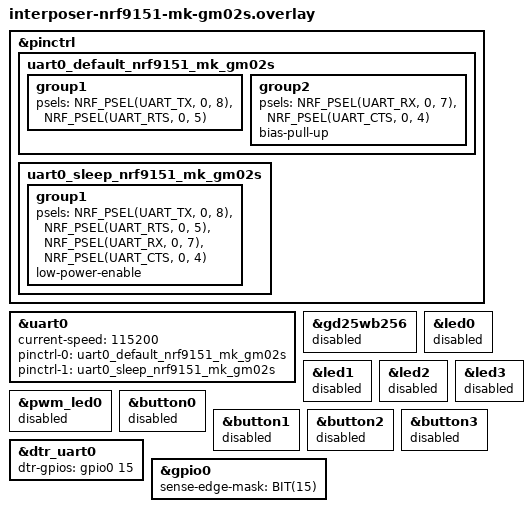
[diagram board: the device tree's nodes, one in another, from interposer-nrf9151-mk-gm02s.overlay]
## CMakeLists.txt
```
#
# Copyright (c) 2019 Nordic Semiconductor
#
# SPDX-License-Identifier: LicenseRef-Nordic-5-Clause
#

cmake_minimum_required(VERSION 3.20.0)

find_package(Zephyr REQUIRED HINTS $ENV{ZEPHYR_BASE})
project(serial_modem)

# NORDIC SDK APP START
target_sources(app PRIVATE src/main.c)
target_sources(app PRIVATE src/sm_util.c)
target_sources(app PRIVATE src/sm_ctrl_pin.c)
target_sources(app PRIVATE src/sm_settings.c)
target_sources(app PRIVATE src/sm_at_host.c)
target_sources(app PRIVATE src/sm_at_commands.c)
target_sources(app PRIVATE src/sm_at_socket.c)
target_sources(app PRIVATE src/sm_uart_handler.c)
target_sources(app PRIVATE src/sm_log.c)
target_sources(app PRIVATE src/sm_at_urc_filter.c)
# NORDIC SDK APP END
target_sources_ifdef(CONFIG_SM_FW_UPDATE app PRIVATE src/sm_fw_update.c)
target_sources_ifdef(CONFIG_SM_FOTA_SESSION app PRIVATE src/sm_fota_session.c)
target_sources_ifdef(CONFIG_SM_FOTA app PRIVATE src/sm_at_fota.c)
target_sources_ifdef(CONFIG_SM_DFU app PRIVATE src/sm_at_dfu.c)
target_sources_ifdef(CONFIG_SM_SMS app PRIVATE src/sm_at_sms.c)
target_sources_ifdef(CONFIG_SM_PPP app PRIVATE src/sm_ppp.c)
target_sources_ifdef(CONFIG_SM_CMUX app PRIVATE src/sm_cmux.c)
target_sources_ifdef(CONFIG_SM_ICMP app PRIVATE src/sm_at_icmp.c)
target_sources_ifdef(CONFIG_SM_GNSS app PRIVATE src/sm_at_gnss.c)
target_sources_ifdef(CONFIG_SM_NRF_CLOUD app PRIVATE src/sm_at_nrfcloud.c)
target_sources_ifdef(CONFIG_SM_NRF_CLOUD_OBSERVABILITY app PRIVATE src/sm_at_nrfcloud_obs.c)
target_sources_ifdef(CONFIG_SM_NRF_CLOUD_FOTA app PRIVATE src/sm_at_nrfcloud_fota.c)
target_sources_ifdef(CONFIG_SM_MQTTC app PRIVATE src/sm_at_mqtt.c)
target_sources_ifdef(CONFIG_SM_COAPC app PRIVATE src/sm_at_coap.c)
target_sources_ifdef(CONFIG_SM_HTTPC app PRIVATE src/sm_at_httpc.c)
target_sources_ifdef(CONFIG_SM_MODEM_TRACE_BACKEND_CMUX app PRIVATE src/sm_trace_backend_cmux.c)
target_sources_ifdef(CONFIG_SM_MODEM_TRACE_BACKEND_UART app PRIVATE src/sm_trace_backend_uart.c)
target_sources_ifdef(CONFIG_NRF_PROVISIONING app PRIVATE src/sm_at_provisioning.c)
target_sources_ifdef(CONFIG_SM_NRF_CLOUD_OBSERVABILITY_LTE_METRICS app PRIVATE src/sm_at_nrfcloud_obs_lte_metrics.c)

add_subdirectory_ifdef(CONFIG_SM_CARRIER src/lwm2m_carrier)

zephyr_include_directories(src)
zephyr_include_directories(memfault)

include(cmake/sm_version.cmake)
```

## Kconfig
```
#
# Copyright (c) 2019 Nordic Semiconductor
#
# SPDX-License-Identifier: LicenseRef-Nordic-5-Clause
#

menu "Nordic Serial Modem"

config HEAP_MEM_POOL_ADD_SIZE_SERIAL_MODEM
	int "Additional heap memory pool size for Serial Modem"
	default 1700 if SM_NRF_CLOUD
	default 0
	help
	  modem_jwt library used by nrf_cloud libraries, uses kernel heap for querying UUID.
	  2x CONFIG_MODEM_JWT_MAX_LEN is the maximum it can use.

config SM_BLOCKING_WORK_Q
	bool
	help
	  Work queue for operations that block for a long time.

config SM_BLOCKING_WORK_Q_STACK_SIZE
	int "Stack size for the blocking operations work queue"
	default 4096
	depends on SM_BLOCKING_WORK_Q

config SM_CUSTOMER_VERSION
	string "Customer version string"
	help
	   This version is reported together with baseline versions by AT command "#XSMVER".

#
# external XTAL for UART
#
config SM_EXTERNAL_XTAL
	bool "Use external XTAL for UARTE"

#
# AT command terminator
#
choice
	prompt "Termination mode"
	default SM_CR_TERMINATION
	help
	  Sets the command terminator used by the serial terminal.
	  Available options are:
	  -  CR termination
	  -  LF termination
	  -  CR+LF termination

config SM_CR_TERMINATION
	bool "CR termination"

config SM_LF_TERMINATION
	bool "LF termination"

config SM_CR_LF_TERMINATION
	bool "CR+LF termination"

endchoice

#
# UART buffers (when CMUX is not in use)
#
config SM_UART_RX_BUF_COUNT
	int "Receive buffers for UART"
	range 2 4
	default 3
	help
	  Amount of buffers for receiving (RX) UART traffic.
	  If the buffers are full, UART RX will be disabled until the buffers are processed.
	  These buffers are not used when CMUX is in use.

config SM_UART_RX_BUF_SIZE
	int "Receive buffer size for UART"
	range 128 4096
	default 2048 if $(dt_nodelabel_enabled,uart0) = y && \
			$(dt_nodelabel_bool_prop,uart0,hw-flow-control) = n
	default 2048 if $(dt_nodelabel_enabled,uart2) = y && \
			$(dt_nodelabel_bool_prop,uart2,hw-flow-control) = n
	default 532 if SM_CMUX
	default 256
	help
	  Amount of received (RX), unprocessed, UART traffic that can be held by single buffer.
	  Increase buffer space if UART0 or UART2 lacks hardware flow control.

config SM_UART_TX_BUF_SIZE
	int "Send buffer size for UART"
	range 128 4096
	default 532 if SM_CMUX
	default 256
	help
	  Amount of UART traffic waiting to be sent (TX), that can be held.
	  If the buffers are full, will send synchronously.

config SM_URC_BUFFER_SIZE
	int "TX buffer size for unsolicited result codes (URC)"
	range 128 4096
	default 4096
	help
	  Buffer, in which unsolicited result codes (URC) are stored before being sent to the host.
	  The buffer has to be large enough to hold the largest URC that can be sent by the modem.
	  Result codes longer than this size will get dropped.

	  The URC in here means an URC from the Modem or from a thread which is not serving sm_work_queue.
	  Messages that are originally sent from sm_work_queue are part of AT-command responses, even though they are indistinguishable from the URCs.

	  This can be reduced if your use cases do not require lengthy notifications.
	  Note: %NCELLMEAS notifications can be nearly 4kB in size,
	  which explains the default value.
	  The maximum value is the size of the buffer that the result codes are formatted in.

config SM_AT_ECHO_MAX_LEN
	int "Maximum length of AT command echo"
	range 2 4096
	default 4096
	help
	  Maximum length of AT command echo that will be sent back to the host when AT command echo is enabled.
	  AT commands longer than this value will be truncated in the echo.
	  The AT command terminator is included in this length and it is always echoed.

config SM_URC_DELAY_WITH_INCOMPLETE_ECHO_MS
	int "Delay for URC transmission when incomplete AT command echo is in progress (ms)"
	default 1000
	help
	  When AT command echo is enabled, and the command is spread over multiple RX buffers,
	  due to its length, or the speed of incoming data (typing), the command echo is considered incomplete
	  until the final part of the command (terminating character) has been received and echoed back to the host.

	  When the AT command echo is incomplete, URC transmissions are delayed by this amount of time for every
	  RX buffer (keystroke, while typing) received until the command echo is complete.

#
# Automatic network attach
#
config SM_AUTO_CONNECT
	bool "Automatically connect to the network on start-up or after a reset"
	help
	  Enables automatic connection to the network using the PDN configuration.

if SM_AUTO_CONNECT

config SM_AUTO_CONNECT_SYSTEM_MODE
	string "System mode for automatic network attach"
	default "1,1,1,0"
	help
	  Defines the default system mode using '%XSYSTEMMODE' AT command for automatic network attach.
	  The format is a comma-separated list of four integers. See the AT command reference for +XSYSTEMMODE for more details.
	  Default value enables LTE-M, NB-IoT, and GNSS, with no LTE preference.

config SM_AUTO_CONNECT_PDN_CONFIG
	bool "PDN configuration for automatic network attach"
	help
	  Enables sending of PDN configuration during automatic network attach.

if SM_AUTO_CONNECT_PDN_CONFIG

config SM_AUTO_CONNECT_PDN_APN
	string "APN for automatic network attach"
	default ""
	help
	  APN to use for automatic network attach.
	  If left empty, the APN configured in the modem will be used.

choice SM_AUTO_CONNECT_PDN_FAMILY
	prompt "PDN family (IP type) for automatic network attach"
	default SM_AUTO_CONNECT_PDN_FAMILY_IPV4V6
	help
	  Select the PDN family (IP address type) to use for automatic network attach.
	  See AT command reference for +CGDCONT for more details.

config SM_AUTO_CONNECT_PDN_FAMILY_IP
	bool "IPv4"
	help
	  Use IPv4 only for the PDN connection.

config SM_AUTO_CONNECT_PDN_FAMILY_IPV6
	bool "IPv6"
	help
	  Use IPv6 only for the PDN connection.

config SM_AUTO_CONNECT_PDN_FAMILY_IPV4V6
	bool "IPv4 and IPv6"
	help
	  Use both IPv4 and IPv6 for the PDN connection (dual stack).

config SM_AUTO_CONNECT_PDN_FAMILY_NON_IP
	bool "Non-IP"
	help
	  Use Non-IP PDN type for the connection.
	  This is used for data transmission without IP headers.

endchoice

config SM_AUTO_CONNECT_PDN_FAMILY_STRING
	string
	default "IP" if SM_AUTO_CONNECT_PDN_FAMILY_IP
	default "IPV6" if SM_AUTO_CONNECT_PDN_FAMILY_IPV6
	default "IPV4V6" if SM_AUTO_CONNECT_PDN_FAMILY_IPV4V6
	default "Non-IP" if SM_AUTO_CONNECT_PDN_FAMILY_NON_IP
	help
	  Internal use only. Represents the selected PDN family as a string.

config SM_AUTO_CONNECT_PDN_AUTH
	int "PDN authentication type for automatic network attach"
	default 0
	range 0 2
	help
	  PDN authentication type to use for automatic network attach.
	  0 = None
	  1 = PAP
	  2 = CHAP

config SM_AUTO_CONNECT_PDN_USERNAME
	string "PDN username for automatic network attach"
	default ""
	help
	  PDN username to use for automatic network attach.
	  Leave empty if no username is required.

config SM_AUTO_CONNECT_PDN_PASSWORD
	string "PDN password for automatic network attach"
	default ""
	help
	  PDN password to use for automatic network attach.
	  Leave empty if no password is required.

endif # SM_AUTO_CONNECT_PDN_CONFIG
endif # SM_AUTO_CONNECT

#
# Data mode
#
config SM_DATAMODE_TERMINATOR
	string "Pattern string to terminate data mode"
	default "+++"
	help
	  Use a pattern to terminate data mode

config SM_DATAMODE_BUF_SIZE
	int "Buffer size for data mode"
	range 1024 8192
	default 4096
	help
	  Size of the buffer for data received in data mode.

#
# Configurable services
#
config SM_SMS
	bool "SMS support"
	default y
	select SMS
	help
	  Support SMS send/receive in plain text

config SM_GNSS
	bool "GNSS support"
	default y

config SM_ICMP
	bool "ICMP ping support"
	default y
	select SM_BLOCKING_WORK_Q
	help
	  Enable the ping command for sending ICMP echo requests.

config SM_COAPC
	bool "CoAP client support"
	default y
	select COAP
	select COAP_CLIENT
	help
	  Enable CoAP client AT commands for making CoAP requests.

config SM_MQTTC
	bool "MQTT client support"
	default y
	select MQTT_LIB
	select MQTT_LIB_TLS

configdefault MQTT_CLEAN_SESSION
	default y if SM_MQTTC

config SM_FULL_FOTA
	bool "Full modem FOTA support"

config SM_DFU_MODEM_FULL
	bool "Full modem DFU support"

config SM_PPP
	bool "PPP support"

config SM_CMUX
	bool "CMUX support"

config SM_CMUX_CHANNEL_COUNT
	int "Number of CMUX channels" if SM_CMUX
	default 4 if SM_CMUX
	default 1 if !SM_CMUX
	range 1 63
	help
	  Number of channels to be used by the CMUX implementation.
	  Each channel adds about 4 kB of RAM usage for buffers.

config SM_DEBUG_STATS_HEAP
	bool "Enable heap usage statistics"
	default y
	select SYS_HEAP_RUNTIME_STATS
	help
	  Enable heap usage statistics for debugging purposes through AT#XDBGSTATSMEM command.
	  The statistics are printed to the log so use AT#XLOG=1 to enable logging.

config SM_DEBUG_STATS_THREAD_STACK
	bool "Enable threads' stack usage statistics"
	depends on SM_DEBUG_STATS_HEAP
	select THREAD_ANALYZER
	select THREAD_NAME
	help
	  Enable threads' stack usage statistics for debugging purposes through
	  the AT#XDBGSTATSMEM command. The statistics are printed to the log so use
	  AT#XLOG=1 to enable logging.
	  With default logging configurations, some of the stack usage metrics are dropped.
	  You need to increase CONFIG_LOG_BUFFER_SIZE to 2048 or more to make it work.
	  This feature will use 4-5 kB of FLASH.

if SM_PPP

config SM_PPP_FALLBACK_MTU
	int "Fallback MTU to be used by PPP"
	default 1280
	help
	  PPP tries to retrieve the cellular link MTU from the modem (using `AT+CGCONTRDP`).
	  If no MTU is returned by the modem, this value will be used as a fallback.
	  The MTU will be used for sending and receiving of data on both the PPP and cellular links.

endif # SM_PPP

if SM_CMUX || SM_PPP

config SM_MODEM_PIPE_TIMEOUT
	int "Timeout for the CMUX and PPP modem pipe operations in seconds"
	default 10

endif # SM_CMUX || SM_PPP

if SM_MQTTC

config SM_MQTTC_MESSAGE_BUFFER_LEN
	int "Size of the buffer for MQTT library"
	default 512
	help
	  Specifies maximum message size that can be transmitted/received through
	  MQTT (excluding MQTT PUBLISH payload).

config SM_MQTTC_VERSION_5_0
	bool "MQTT 5.0 support [EXPERIMENTAL]"
	default y
	help
	  Build the MQTT library with MQTT 5.0 protocol support.
	  The MQTT client uses MQTT 3.1.1 unless MQTT 5.0 is selected with
	  the AT#XMQTTCFG command.

choice MQTT_VERSION_SUPPORT
	default MQTT_VERSION_5_0 if SM_MQTTC_VERSION_5_0
endchoice

config SM_MQTTC_TOPIC_ALIAS_MAX
	int "Maximum number of outgoing MQTT 5.0 topic aliases"
	depends on SM_MQTTC_VERSION_5_0
	range 0 16
	default 4
	help
	  Number of topic aliases the MQTT client assigns to the topics of its own
	  MQTT 5.0 publications, limited by the broker's Topic Alias Maximum.
	  Repeated publications to an aliased topic omit the topic name.
	  Each alias uses about 130 bytes of heap while connected.
	  Set to 0 to disable outgoing topic aliases.
	  MQTT_TOPIC_ALIAS_MAX is a separate MQTT library option that limits the
	  topic aliases the broker uses in messages to the client.

# Incoming topic names can be longer than any fixed alias buffer, because wildcard
# subscriptions match topics of any length. The library drops the connection when an
# aliased topic does not fit, so do not advertise topic alias support by default.
# To enable, also set MQTT_TOPIC_ALIAS_STRING_MAX to at least SM_MQTTC_MESSAGE_BUFFER_LEN.
configdefault MQTT_TOPIC_ALIAS_MAX
	default 0

endif # SM_MQTTC

if SM_GNSS

config SM_GNSS_OUTPUT_NMEA_SATELLITES
	bool "Output NMEA satellite messages (GSV, GSA)"
	default y if SM_LOG_LEVEL_DBG
	depends on SM_LOG_LEVEL_DBG
	help
	  If enabled, NMEA messages that pertain to the satellites will be output
	  along with the other NMEA messages. Those are output in debug logs.

config SM_PGPS_INJECT_FIX_DATA
	bool "Inject the data obtained when acquiring a fix"
	default y
	depends on SM_GNSS
	depends on SM_NRF_CLOUD
	depends on NRF_CLOUD_PGPS
	help
	  If enabled, when a fix is acquired the current location and time will
	  be passed to the P-GPS subsystem.
	  It allows to speed up the time it takes to acquire the next fix when
	  A-GNSS is disabled or unavailable.
	  This can be detrimental to short TTFF if the device is expected to move
	  distances longer than a few dozen kilometers between fix attempts.
	  In that case this option should be disabled.

endif # SM_GNSS

config SM_HTTPC
	bool "HTTP client support"
	default y
	help
	  Enable HTTP client AT commands for making HTTP/HTTPS requests.
	  Uses non-blocking socket API with XAPOLL for asynchronous
	  event-driven I/O.

if SM_HTTPC

config SM_HTTPC_RESPONSE_TIMEOUT_MS
	int "HTTP client idle timeout (ms)"
	range 1000 300000
	default 30000
	help
	  The timer is a sliding window: it resets each time data is sent or
	  received (request headers, body upload chunks, response body chunks).
	  If no activity occurs within this window the request is aborted and
	  ``#XHTTPCSTAT: <fd>,-1,<bytes>`` is reported.
	  A periodic background scan enforces the deadline even when the
	  server stalls silently without closing the TCP connection.

endif # SM_HTTPC

if NRF_MODEM_LIB_TRACE

choice NRF_MODEM_LIB_TRACE_BACKEND

config SM_MODEM_TRACE_BACKEND_CMUX
	bool "CMUX modem trace backend"
	depends on SM_CMUX_CHANNEL_COUNT > 2
	help
	  When CMUX is enabled, modem traces are transmitted on a dedicated CMUX channel.
	  The trace channel is the first channel after the AT command channel and the PPP channel.

config SM_MODEM_TRACE_BACKEND_UART
	bool "UART modem trace backend (shared with Zephyr log backend)"
	depends on UART_ASYNC_API
	help
	  Uses the zephyr,console UART as the modem trace backend, sharing it
	  with the Zephyr application log backend. The two are mutually exclusive:
	  only one can be active at a time. Switch at runtime with AT#XLOG / AT#XTRACE.

endchoice # NRF_MODEM_LIB_TRACE_BACKEND

endif

#
# Hardware RX byte counting for UART
#
# Either hardware flow control OR hardware RX byte counting is required to prevent RX data loss.
# When hw-flow-control is enabled in devicetree, it handles flow management efficiently.
# When hw-flow-control is disabled, hardware RX byte counting is enabled to prevent data loss,
# but it consumes more power due to additional timer usage.
#
if UART_ASYNC_API

config UART_0_NRF_HW_ASYNC
	default y if HAS_HW_NRF_UARTE0 && !$(dt_nodelabel_bool_prop,uart0,hw-flow-control)

config UART_0_NRF_HW_ASYNC_TIMER
	default 0 if HAS_HW_NRF_UARTE0 && !$(dt_nodelabel_bool_prop,uart0,hw-flow-control)

config UART_2_NRF_HW_ASYNC
	default y if HAS_HW_NRF_UARTE2 && !$(dt_nodelabel_bool_prop,uart2,hw-flow-control)

config UART_2_NRF_HW_ASYNC_TIMER
	default 2 if HAS_HW_NRF_UARTE2 && !$(dt_nodelabel_bool_prop,uart2,hw-flow-control)

endif # UART_ASYNC_API

module = SM
module-str = serial modem
source "$(ZEPHYR_BASE)/subsys/logging/Kconfig.template.log_config"

rsource "src/lwm2m_carrier/Kconfig"

endmenu

# Must be sourced before Kconfig.zephyr, see the respective files for the reason why.
rsource "Kconfig.nrf_cloud"
rsource "Kconfig.memfault"

source "Kconfig.zephyr"
```

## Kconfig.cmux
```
#
# Copyright (c) 2026 Nordic Semiconductor ASA
#
# SPDX-License-Identifier: LicenseRef-Nordic-5-Clause
#

# Application defaults for CMUX, which is enabled by setting CONFIG_SM_CMUX=y.
#
# This file must be sourced before Kconfig.zephyr, which is what pulls in the Kconfig of
# the Zephyr modem subsystem: a default is inserted at the position where it appears
# relative to the definition of the symbol, and the first matching default wins. Sourced
# afterwards, every default here would silently lose to the one of the module.

if SM_CMUX

# Enable the Zephyr modem CMUX multiplexer.
configdefault MODEM_CMUX
	default y

# Set CMUX MTU to 127 bytes to align with the Linux gsm_mux driver default.
configdefault MODEM_CMUX_MTU
	default 127

# Extra work-buffer space for CMUX frame assembly.
# 127 (MTU) + 272 (header + flag overhead per frame) = 399 bytes.
configdefault MODEM_CMUX_WORK_BUFFER_SIZE_EXTRA
	default 399

endif # SM_CMUX
```

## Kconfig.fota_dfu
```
#
# Copyright (c) 2026 Nordic Semiconductor ASA
#
# SPDX-License-Identifier: LicenseRef-Nordic-5-Clause
#

# Firmware update features, together with the Kconfig defaults they pull in.
#
# SM_FOTA enables the AT#XFOTA command (firmware download over HTTP/HTTPS).
# SM_DFU  enables the AT#XDFU* commands (local firmware upload).
#
# Features that update the firmware, including SM_NRF_CLOUD_FOTA and the LwM2M carrier library,
# share the code that is behind the hidden symbols below:
# - SM_FOTA_SESSION: the state of a FOTA session and the reporting of its result.
# - SM_FW_UPDATE: the functionality common to all firmware updates, like the confirmation
#   of a new application image.
#
# This file must be sourced before Kconfig.zephyr, see Kconfig.nrf_cloud for the reason why.

config SM_FOTA
	bool "FOTA (Firmware Over-The-Air) support"
	default y
	select HTTP_PARSER_URL
	help
	  Enable FOTA support via the AT#XFOTA command.

config SM_FULL_FOTA
	bool "Full modem FOTA support"
	depends on SM_FOTA

config SM_DFU
	bool "DFU (Device Firmware Update) support"
	default y
	help
	  Enable DFU support via the AT#XDFUINIT, AT#XDFUWRITE and AT#XDFUAPPLY commands.

config SM_DFU_MODEM_FULL
	bool "Full modem DFU support"
	depends on SM_DFU

config SM_FOTA_SESSION
	bool
	default y if SM_FOTA || SM_NRF_CLOUD_FOTA

config SM_FW_UPDATE
	bool
	default y if SM_FOTA_SESSION || SM_DFU

# The LwM2M carrier library depends on DOWNLOADER and DFU_TARGET, so the hidden symbols cannot
# depend on it, as that would make a dependency loop. SM_CARRIER depends on SM_FOTA_SESSION instead.

if SM_FOTA_SESSION

# FOTA download library: handles OTA download and DFU target selection.
configdefault FOTA_DOWNLOAD
	default y

configdefault FOTA_DOWNLOAD_PROGRESS_EVT
	default y

# Downloader library used by fota_download.
configdefault DOWNLOADER
	default y

configdefault DOWNLOADER_STACK_SIZE
	default 4096

configdefault DOWNLOADER_MAX_FILENAME_SIZE
	default 2048

# Progressive slot erase during FOTA download.
configdefault IMG_ERASE_PROGRESSIVELY
	default y

endif # SM_FOTA_SESSION

if SM_FW_UPDATE

# DFU target library: used by FOTA (streaming download targets) and DFU
# (direct write targets: MCUboot, modem delta, full modem).
configdefault DFU_TARGET
	default y

# Stream flash: required internally by the DFU target library for all targets
# that write to flash in chunks.
configdefault STREAM_FLASH
	default y

# MCUboot image manager: required for confirming and scheduling MCUboot updates.
configdefault IMG_MANAGER
	default y

# MCUboot bootloader FOTA requires fw_info to validate the update after reboot.
configdefault FW_INFO
	default y

endif # SM_FW_UPDATE
```

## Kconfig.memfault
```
#
# Copyright (c) 2026 Nordic Semiconductor ASA
#
# SPDX-License-Identifier: LicenseRef-Nordic-5-Clause
#

# Application defaults for nRF Cloud observability and FOTA, i.e., Memfault features.
#
# This file must be sourced before Kconfig.zephyr, which is what pulls in the Kconfig of
# the Memfault module: a default is inserted at the position where it appears relative to
# the definition of the symbol, and the first matching default wins. Sourced afterwards,
# every default here would silently lose to the one of the module.

# Enable Memfault when the observability or FOTA features are on.
# Disable explicitly with CONFIG_MEMFAULT=n (no_memfault build), or automatically when both
# SM_NRF_CLOUD_OBSERVABILITY and SM_NRF_CLOUD_FOTA are disabled.
# Note: SM_NRF_CLOUD_OBSERVABILITY and SM_NRF_CLOUD_FOTA intentionally do not depend on
# MEMFAULT or MEMFAULT_USE_NRF_CLOUD_COAP. Those dependencies would be circular here.
# MEMFAULT_USE_NRF_CLOUD_COAP is enabled via its own configdefault below once MEMFAULT=y.
configdefault MEMFAULT
	default y if SM_NRF_CLOUD_OBSERVABILITY || SM_NRF_CLOUD_FOTA

config SM_NRF_CLOUD_OBSERVABILITY
	bool "nRF Cloud observability AT commands"
	default y
	depends on SM_NRF_CLOUD
	select BASE64
	help
	  Enables the ``AT#XNRFCLOUDOBS*`` commands, which control the Memfault data upload
	  over the nRF Cloud CoAP transport.
	  This requires :option:`CONFIG_SM_NRF_CLOUD`.
	  See :ref:`SM_AT_NRFCLOUDOBS` for more information.

config SM_NRF_CLOUD_OBSERVABILITY_AUTO_INTERVAL_SECONDS
	int "Default interval of the automatic upload"
	depends on SM_NRF_CLOUD_OBSERVABILITY
	default 3600
	range 60 86400
	help
	  Interval, in seconds, used by ``AT#XNRFCLOUDOBSAUTO`` when the host enables the
	  automatic upload without giving one, and no interval has been stored
	  yet. The interval the host gives is persistent, so this value only
	  applies until the host configures one.
	  It defaults to one hour.
	  This requires :option:`CONFIG_SM_NRF_CLOUD_OBSERVABILITY` to be enabled.

config SM_NRF_CLOUD_OBSERVABILITY_DEBUG
	bool "Debug nRF Cloud observability AT commands"
	depends on SM_NRF_CLOUD_OBSERVABILITY
	help
	  Enable the debug observability commands:

	  * ``AT#XNRFCLOUDOBSDEVINFO`` returns the Memfault device information.
	  * ``AT#XNRFCLOUDOBSCRASH`` forces a crash so that coredump capture and
	    upload can be tested.
	  * ``AT#XNRFCLOUDOBSEXPORT`` prints the buffered Memfault chunks to the AT
	    interface instead of uploading them.

	  This is disabled by default: ``AT#XNRFCLOUDOBSCRASH`` deliberately crashes
	  the application, so enable it only in development builds.
	  This requires :option:`CONFIG_SM_NRF_CLOUD_OBSERVABILITY` to be enabled.

config SM_NRF_CLOUD_OBSERVABILITY_LTE_METRICS
	bool "Collect additional LTE metrics via AT commands for Memfault"
	depends on MEMFAULT
	depends on MEMFAULT_NCS_LTE_METRICS
	depends on SM_NRF_CLOUD_OBSERVABILITY
	default y
	help
	  Collect cell ID, tracking area code, LTE mode, PSM (TAU and active time) and
	  eDRX (interval and paging time window) metrics on each Memfault heartbeat.
	  Also track time to connect, connection-loss count, and LTE on-time.
	  It is enabled by default.
	  This requires :option:`CONFIG_SM_NRF_CLOUD_OBSERVABILITY`.

config SM_NRF_CLOUD_FOTA
	bool "nRF Cloud FOTA AT commands"
	default y
	depends on SM_NRF_CLOUD
	help
	  Enables the ``AT#XNRFCLOUDFOTA*`` commands, which check for and download
	  application and modem firmware updates using `Memfault release management`_,
	  delivered over the same nRF Cloud CoAP transport as ``AT#XNRFCLOUDOBS*``.
	  This requires :option:`CONFIG_SM_NRF_CLOUD`.
	  See :ref:`SM_AT_NRFCLOUDFOTA` for more information.

# Report a statically configured firmware version. A choice symbol cannot be given a
# configdefault, which warns that it has no effect, so the default of the choice itself is
# overridden instead. Assigning the symbol in prj.conf would warn with CONFIG_MEMFAULT=n.
choice MEMFAULT_FW_VERSION
	default MEMFAULT_NCS_FW_VERSION_STATIC
endchoice

configdefault MEMFAULT_LOGGING_ENABLE
	default y

# The whole buffer is a static RAM array captured via .bss regardless of how much of it is in use.
configdefault MEMFAULT_LOGGING_RAM_SIZE
	default 4096 if $(dt_nodelabel_exists,memfault_coredump_partition)

# Return from the fault handler to allow Zephyr's default fatal error handler to take over.
configdefault MEMFAULT_FAULT_HANDLER_RETURN
	default y

configdefault MEMFAULT_RAM_BACKED_COREDUMP_SIZE
	default 4096

# The flash-backed coredump is enabled automatically when the board's devicetree defines a
# memfault_coredump_partition falling back to a RAM-backed coredump otherwise.
configdefault MEMFAULT_NCS_INTERNAL_FLASH_BACKED_COREDUMP
	default y if $(dt_nodelabel_exists,memfault_coredump_partition)

# Crashing thread benefits from a deep stack capture.
configdefault MEMFAULT_COREDUMP_ACTIVE_TASK_STACK_SIZE_TO_COLLECT
	default 2048 if $(dt_nodelabel_exists,memfault_coredump_partition)

# The ~13 other blocked / idle threads need to show a couple of frames to tell
# what the thread was waiting on.
configdefault MEMFAULT_COREDUMP_STACK_SIZE_TO_COLLECT
	default 256

configdefault MEMFAULT_COREDUMP_MAX_TRACKED_TASKS
	default 16

# Disable .data collection.
configdefault MEMFAULT_COREDUMP_COLLECT_DATA_REGIONS
	default n

# Collect heap statistics in coredumps.
configdefault MEMFAULT_HEAP_STATS
	default y

# Upload Memfault data via the nRF Cloud CoAP transport.
configdefault MEMFAULT_USE_NRF_CLOUD_COAP
	default y

configdefault MEMFAULT_HTTP_ENABLE
	default n

# The periodic upload port is not used: AT#XNRFCLOUDOBSAUTO implements the automatic upload
# itself, with an interval that the host can change, and every other upload is host-driven
# with AT#XNRFCLOUDOBSUPLOAD.
configdefault MEMFAULT_PERIODIC_UPLOAD
	default n

# Enabled by SM_NRF_CLOUD_FOTA (AT#XNRFCLOUDFOTA*); no backend is wired up otherwise.
configdefault MEMFAULT_ZEPHYR_FOTA
	default y if SM_NRF_CLOUD_FOTA
	default n

configdefault MEMFAULT_FOTA_DOWNLOAD_CALLBACK_CUSTOM
	default y if SM_NRF_CLOUD_FOTA

configdefault MEMFAULT_FOTA_MODEM_UPDATE
	default y if SM_NRF_CLOUD_FOTA

configdefault NRF_CLOUD_FOTA_POLL
	default y if SM_NRF_CLOUD_FOTA

# Collect metrics for unused stack space.
configdefault MEMFAULT_NCS_STACK_METRICS
	default n

# Collect the LTE metrics that MODEM_INFO provides: modem firmware version, operator, RSRP,
# SNR, band and the connectivity statistics. The remaining LTE metrics are collected via
# AT commands in sm_at_nrfcloud_obs_lte_metrics.c.
configdefault MEMFAULT_NCS_LTE_METRICS
	default y

configdefault MEMFAULT_USER_CONFIG_ENABLE
	default y if SM_NRF_CLOUD_OBSERVABILITY_LTE_METRICS

configdefault MEMFAULT_NCS_IMPLEMENT_METRICS_COLLECTION
	default n if SM_NRF_CLOUD_OBSERVABILITY_LTE_METRICS

# Memfault depends on POSIX, disable unneeded POSIX features.
configdefault POSIX_FILE_SYSTEM
	default n if MEMFAULT

# The Memfault CoAP port (memfault_platform_coap.c) allocates the packetizer buffer with
# k_calloc, and it fails to build unless CONFIG_HEAP_MEM_POOL_SIZE is greater than zero. A
# HEAP_MEM_POOL_ADD_SIZE_* option is not enough, because the port tests this symbol
# directly. Zephyr uses the greater of this value and the sum of the
# HEAP_MEM_POOL_ADD_SIZE_* options, so this does not shrink the pool of other subsystems.
configdefault HEAP_MEM_POOL_SIZE
	default 4096 if MEMFAULT

# MEMFAULT_USE_NRF_CLOUD_COAP requires at least two user CoAP options (the project key for
# the chunks resource, and PROXY_URI plus the project key for the proxy resource), an
# extended options length value of at least 192, and room for four extra CoAP client
# options.
configdefault NRF_CLOUD_COAP_MAX_USER_OPTIONS
	default 2 if MEMFAULT

configdefault COAP_EXTENDED_OPTIONS_LEN_VALUE
	default 192 if MEMFAULT
	default 96

configdefault COAP_CLIENT_MAX_EXTRA_OPTIONS
	default 4 if MEMFAULT

configdefault COAP_CLIENT_MAX_PATH_LENGTH
	default 160 if MEMFAULT_USE_NRF_CLOUD_COAP

# The larger CoAP options above (COAP_EXTENDED_OPTIONS_LEN_VALUE and
# COAP_CLIENT_MAX_EXTRA_OPTIONS) enlarge struct coap_client_request, which the
# nRF Provisioning thread builds on its stack in send_coap_request(),
# so the stack size must be increased to accommodate it.
configdefault NRF_PROVISIONING_STACK_SIZE
	default 2560 if MEMFAULT
```

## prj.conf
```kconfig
#
# Copyright (c) 2020 Nordic Semiconductor ASA
#
# SPDX-License-Identifier: LicenseRef-Nordic-5-Clause
#
# General config
CONFIG_LOG=y
CONFIG_ASSERT=y
CONFIG_ASSERT_VERBOSE=n
CONFIG_LOG_DEFAULT_LEVEL=3
CONFIG_STACK_SENTINEL=y
CONFIG_PICOLIBC_IO_FLOAT=y
CONFIG_RING_BUFFER=y
CONFIG_REBOOT=y
CONFIG_EVENTFD=y
CONFIG_NCS_APPLICATION_BOOT_BANNER_STRING="Serial Modem"

# Enable UART logging by default.
CONFIG_UART_CONSOLE=y
CONFIG_LOG_BACKEND_UART=y
# Logging starts automatically, but it is disabled after bootup.
CONFIG_LOG_BACKEND_UART_AUTOSTART=y

# Disable Segger RTT logging by default.
CONFIG_USE_SEGGER_RTT=n
CONFIG_RTT_CONSOLE=n
CONFIG_LOG_BACKEND_RTT=n
# Optional: when RTT logging is enabled, increase the RTT buffer so that
# all Serial Modem boot logs fit into the buffer.
#CONFIG_SEGGER_RTT_BUFFER_SIZE_UP=2048

# Enable Serial Modem debug logging by default. This is required for AT#XLOG=2.
CONFIG_SM_LOG_LEVEL_DBG=y

# Network
CONFIG_NETWORKING=y
CONFIG_NET_SOCKETS=y
CONFIG_NET_NATIVE=n
CONFIG_NET_IPV4=y
CONFIG_NET_IPV6=y

# Modem library
CONFIG_NRF_MODEM_LIB=y
CONFIG_AT_CMD_CUSTOM=y

# Modem pipe
CONFIG_MODEM_MODULES=y
CONFIG_MODEM_PIPE=y
CONFIG_MODEM_CMUX=y

# Handle modem fault
CONFIG_NRF_MODEM_LIB_ON_FAULT_APPLICATION_SPECIFIC=y

# Use GPIO
CONFIG_GPIO=y
CONFIG_GPIO_NRFX=y

# UART interface
CONFIG_SERIAL=y
CONFIG_UART_USE_RUNTIME_CONFIGURE=y
CONFIG_UART_ASYNC_API=y
CONFIG_UART_INTERRUPT_DRIVEN=n

# Stacks and heaps
CONFIG_MAIN_STACK_SIZE=2048
CONFIG_SYSTEM_WORKQUEUE_STACK_SIZE=4096
CONFIG_AT_MONITOR_HEAP_SIZE=4096
CONFIG_COMMON_LIBC_MALLOC=y
CONFIG_COMMON_LIBC_MALLOC_ARENA_SIZE=-1

# Device power management
CONFIG_PM_DEVICE=y
CONFIG_PM_DEVICE_RUNTIME=n

# FLASH
CONFIG_FLASH=y
CONFIG_FLASH_PAGE_LAYOUT=y
CONFIG_FLASH_MAP=y
CONFIG_MPU_ALLOW_FLASH_WRITE=y

# Settings
CONFIG_SETTINGS=y
CONFIG_SETTINGS_NVS=y
CONFIG_NVS=y

# Reset on fatal error instead of halting.
CONFIG_RESET_ON_FATAL_ERROR=y

# CoAP client settings
CONFIG_COAP_CLIENT_BLOCK_SIZE=512
CONFIG_COAP_CLIENT_MESSAGE_SIZE=576
CONFIG_COAP_CLIENT_THREAD_PRIORITY=0
# COAP_EXTENDED_OPTIONS_LEN_VALUE and COAP_CLIENT_MAX_EXTRA_OPTIONS are set in
# Kconfig.memfault, which bumps them when Memfault is enabled.
CONFIG_COAP_CLIENT_STACK_SIZE=2048

# UUID and JWT
CONFIG_MODEM_JWT=y

# Disabling antenna configurations since GNSS uses external antenna by default.
# Modem antenna library is enabled by default for nRF9151DK with onboard antenna configuration.
# If you need to use the onboard antenna, use "AT%XCOEX0=1,1,1565,1586" command.
CONFIG_MODEM_ANTENNA=n

# AT command helper libraries
CONFIG_AT_PARSER=y
CONFIG_AT_MONITOR=y

# SMS
CONFIG_SMS_STATUS_REPORT=n

# Eventfd's to use with AT-commands.
CONFIG_ZVFS_EVENTFD_MAX=2

# TF-M
CONFIG_TFM_PROFILE_TYPE_MINIMAL=y
# Disable TF-M log sending as it will block until remote end is ready, when HWFC is used on UART1.
CONFIG_TFM_LOG_LEVEL_SILENCE=y

# debug options
#CONFIG_LOG_BUFFER_SIZE=16384
#CONFIG_LOG_PRINTK=n
#CONFIG_LOG_MODE_IMMEDIATE=y
#CONFIG_DEBUG_OPTIMIZATIONS=y
#CONFIG_DTR_UART_LOG_LEVEL_DBG=y
```

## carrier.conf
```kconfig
#
# Copyright (c) 2022 Nordic Semiconductor ASA
#
# SPDX-License-Identifier: LicenseRef-Nordic-5-Clause
#

CONFIG_LWM2M_CARRIER=y

# LwM2M carrier is only compiled for hard-float
CONFIG_FPU=y
CONFIG_FP_HARDABI=y

# The carrier requires the FOTA session, which is provided by AT#XFOTA
CONFIG_SM_FOTA=y

# Download client for DFU
CONFIG_DOWNLOADER_MAX_FILENAME_SIZE=416

# Modem info
CONFIG_MODEM_INFO=y
CONFIG_MODEM_INFO_ADD_DATE_TIME=n
CONFIG_MODEM_INFO_BUFFER_SIZE=512

# Enable LwM2M carrier support
CONFIG_SM_CARRIER=y
CONFIG_SM_AUTO_CONNECT=y
CONFIG_SM_CUSTOMER_VERSION="lwm2m_carrier"

# Enable LwM2M carrier settings support
CONFIG_LWM2M_CARRIER_SETTINGS=y

# DFU target library
CONFIG_DFU_TARGET=y

# IPv4 (IPv6 is enabled by default)
CONFIG_NET_IPV4=y

# We need CONFIG_HEAP_MEM_POOL_SIZE>=4096 for CONFIG_LWM2M_CARRIER.
# Final size will be determined by the build system by adding all
# HEAP_MEM_POOL_ADD_SIZE_* together.
CONFIG_HEAP_MEM_POOL_SIZE=4096

# Drop nRF Cloud features to save flash
CONFIG_SM_NRF_CLOUD=n
CONFIG_MEMFAULT=n
```

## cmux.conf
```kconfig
#
# Copyright (c) 2023 Nordic Semiconductor ASA
#
# SPDX-License-Identifier: LicenseRef-Nordic-5-Clause
#

CONFIG_SM_CMUX=y

# Zephyr modem subsystem
CONFIG_MODEM_MODULES=y
CONFIG_MODEM_CMUX=y

# Align defaults with Linux
CONFIG_MODEM_CMUX_MTU=127
CONFIG_MODEM_CMUX_WORK_BUFFER_SIZE_EXTRA=399

CONFIG_SM_UART_RX_BUF_COUNT=3

# debug options
#CONFIG_MODEM_CMUX_LOG_LEVEL_DBG=y
#CONFIG_MODEM_MODULES_LOG_LEVEL_DBG=y
```

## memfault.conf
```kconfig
#
# Copyright (c) 2025 Nordic Semiconductor
#
# SPDX-License-Identifier: LicenseRef-Nordic-5-Clause
#

CONFIG_MEMFAULT=y
CONFIG_MEMFAULT_HTTP_PERIODIC_UPLOAD=y
CONFIG_MODEM_KEY_MGMT=y
CONFIG_MEMFAULT_LOGGING_ENABLE=y
CONFIG_MEMFAULT_HTTP_ENABLE=y
CONFIG_MEMFAULT_NCS_LTE_METRICS=y
CONFIG_MEMFAULT_NCS_STACK_METRICS=y
CONFIG_MEMFAULT_NCS_INTERNAL_FLASH_BACKED_COREDUMP=y
CONFIG_MEMFAULT_NCS_DEVICE_ID_HW_ID=y
CONFIG_MEMFAULT_LOGGING_RAM_SIZE=4096
CONFIG_MEMFAULT_HEAP_STATS=y
CONFIG_HEAP_MEM_POOL_SIZE=4096
CONFIG_MEMFAULT_HTTP_DEDICATED_WORKQUEUE_STACK_SIZE=1560
CONFIG_MEMFAULT_COREDUMP_FULL_THREAD_STACKS=y
CONFIG_MEMFAULT_EVENT_STORAGE_SIZE=2048
CONFIG_MEMFAULT_NCS_POST_COREDUMP_ON_NETWORK_CONNECTED=y
CONFIG_LTE_LINK_CONTROL=y
CONFIG_LTE_LC_EDRX_MODULE=y
CONFIG_LTE_LC_PSM_MODULE=y
CONFIG_LTE_LC_PDN_MODULE=y
CONFIG_PSA_WANT_ALG_SHA_1=y

# Use IMEI as HW ID
CONFIG_HW_ID_LIBRARY_SOURCE_IMEI=y

# Memfault depends on POSIX, disable unneeded POSIX features
CONFIG_POSIX_FILE_SYSTEM=n
```

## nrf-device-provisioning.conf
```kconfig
#
# Copyright (c) 2026 Nordic Semiconductor ASA
#
# SPDX-License-Identifier: LicenseRef-Nordic-5-Clause
#

CONFIG_NRF_PROVISIONING=y
CONFIG_NRF_PROVISIONING_HTTP=n
CONFIG_NRF_PROVISIONING_COAP=y
CONFIG_NRF_PROVISIONING_WITH_CERT=y
CONFIG_NRF_PROVISIONING_ROOT_CA_SEC_TAG=42384
CONFIG_NRF_PROVISIONING_PROVIDE_ATTESTATION_TOKEN=y
CONFIG_NRF_PROVISIONING_LOG_LEVEL_INF=y
CONFIG_NRF_PROVISIONING_HEAP_SYSTEM=y

# Three concurrent CoAP client instances are required: one for nRF Device Provisioning,
# one for AT#XCOAPCREQ requests, and one for AT#XNRFCLOUD CoAP-based cloud communication.
CONFIG_COAP_CLIENT_MAX_INSTANCES=3

# Timeout for waiting for the modem to enter the desired connectivity state during provisioning.
CONFIG_NRF_PROVISIONING_MODEM_STATE_WAIT_TIMEOUT_SECONDS=120

# Scheduled provisioning is not needed for Serial Modem, as the provisioning is triggered by the host.
CONFIG_NRF_PROVISIONING_SCHEDULED=n
CONFIG_NRF_PROVISIONING_AUTO_START_ON_INIT=n

# Provisioning message content format
CONFIG_NRF_PROVISIONING_CODEC=y
CONFIG_NRF_PROVISIONING_CBOR=y
CONFIG_ZCBOR=y

# Max provisioning commands in a single provisioning exchange
CONFIG_NRF_PROVISIONING_CBOR_RECORDS=5

# Adjust provisioning and buffer sizes to handle nRF Cloud certs
CONFIG_NRF_PROVISIONING_RX_BUF_SZ=2304
CONFIG_NRF_PROVISIONING_TX_BUF_SZ=2304
CONFIG_NRF_PROVISIONING_CODEC_AT_CMD_LEN=2048

# CoAP client
CONFIG_COAP=y
CONFIG_COAP_EXTENDED_OPTIONS_LEN=y
CONFIG_COAP_CLIENT=y

# Modem key management
CONFIG_MODEM_KEY_MGMT=y
CONFIG_MODEM_ATTEST_TOKEN=y

# Modem info
CONFIG_MODEM_INFO=y
```

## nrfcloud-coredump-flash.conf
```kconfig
#
# Copyright (c) 2026 Nordic Semiconductor
#
# SPDX-License-Identifier: LicenseRef-Nordic-5-Clause
#
# Memfault: adds a flash-backed coredump on top of the default
# build (see prj.conf). Apply together with nrfcloud-coredump-flash.overlay,
# which carves the coredump flash partition by shrinking
# the MCUboot application slots by 8 KiB each. Use only where the flash budget allows (it
# reserves a 16 KiB coredump partition).
#

# Store the coredump in the dedicated memfault_coredump_partition (16 KiB) defined
# in nrfcloud-coredump-flash.overlay.
CONFIG_MEMFAULT_NCS_INTERNAL_FLASH_BACKED_COREDUMP=y
CONFIG_MEMFAULT_COREDUMP_STACK_SIZE_TO_COLLECT=1024
```

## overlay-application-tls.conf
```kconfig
#
# Copyright (c) 2026 Nordic Semiconductor ASA
#
# SPDX-License-Identifier: LicenseRef-Nordic-5-Clause
#

CONFIG_TFM_PROFILE_TYPE_NOT_SET=y

CONFIG_TFM_PARTITION_PLATFORM=y
CONFIG_TFM_PARTITION_CRYPTO=y
CONFIG_TFM_PARTITION_INTERNAL_TRUSTED_STORAGE=y
CONFIG_TFM_PARTITION_PROTECTED_STORAGE=y
CONFIG_TFM_PARTITION_INITIAL_ATTESTATION=n
# Max asset size for PS. Default is 2048; certificate chains up to ~3.7 kB
# require at least 3800. Setting to the hardware maximum (4024).
# This also automatically raises TFM_CRYPTO_IOVEC_BUFFER_SIZE to 8192,
# which is needed to transfer larger credentials through the TF-M IPC boundary.
CONFIG_TFM_PS_MAX_ASSET_SIZE=4024

# Disable IPC to save RAM
CONFIG_TFM_IPC=n
CONFIG_TFM_SFN=y


CONFIG_TLS_CREDENTIALS=y
CONFIG_TLS_CREDENTIALS_BACKEND_PROTECTED_STORAGE=y
CONFIG_SM_APP_TLS=y

# Dispatch TLS sockets to MbedTLS; underlying TCP socket remains modem-offloaded
CONFIG_NET_SOCKETS_OFFLOAD_DISPATCHER=y

# PSA crypto
CONFIG_PSA_CRYPTO=y

# TLS sockets
CONFIG_NET_SOCKETS_SOCKOPT_TLS=y
CONFIG_NET_SOCKETS_TLS_MAX_CONTEXTS=2
CONFIG_NET_SOCKETS_TLS_SET_MAX_FRAGMENT_LENGTH=y
CONFIG_NET_SOCKETS_CONNECT_TIMEOUT=30000
CONFIG_ZVFS_OPEN_MAX=10
CONFIG_NET_IPV4=y

# DTLS
CONFIG_MBEDTLS_SSL_PROTO_DTLS=y
CONFIG_MBEDTLS_SSL_DTLS_CONNECTION_ID=y
CONFIG_NET_SOCKETS_ENABLE_DTLS=y

# MbedTLS core
CONFIG_MBEDTLS=y
CONFIG_MBEDTLS_ENABLE_HEAP=y
# 32 KB fits one handshake at a time (sequential AT command flow).
# 48 KB needed if two contexts can handshake simultaneously.
# 64 KB (original) for maximum safety with 8 KB cert chains on both contexts.
CONFIG_MBEDTLS_HEAP_SIZE=49152
CONFIG_MBEDTLS_SSL_PROTO_TLS1_2=y
CONFIG_MBEDTLS_SSL_SERVER_NAME_INDICATION=y
CONFIG_MBEDTLS_SSL_SRV_C=y
CONFIG_MBEDTLS_SSL_IN_CONTENT_LEN=8192
CONFIG_MBEDTLS_SSL_OUT_CONTENT_LEN=4096
CONFIG_MBEDTLS_PEM_PARSE_C=y
CONFIG_MBEDTLS_MD_C=y
CONFIG_MBEDTLS_HMAC_DRBG_C=y

# System heap for k_malloc() used by PS backend to load credentials into RAM
# Peak = TLS_MAX_CREDENTIALS_NUMBER slots * ~2 kB each + allocator overhead
CONFIG_TLS_MAX_CREDENTIALS_NUMBER=3
CONFIG_HEAP_MEM_POOL_SIZE=8192

# AES
CONFIG_PSA_WANT_KEY_TYPE_AES=y
CONFIG_PSA_WANT_ALG_CCM=y
CONFIG_PSA_WANT_ALG_GCM=y
CONFIG_PSA_WANT_ALG_CBC_NO_PADDING=y
CONFIG_PSA_WANT_ALG_CBC_PKCS7=y

# ECC
CONFIG_PSA_WANT_ECC_SECP_R1_256=y
CONFIG_PSA_WANT_ECC_SECP_R1_384=y
CONFIG_PSA_WANT_KEY_TYPE_ECC_KEY_PAIR_IMPORT=y
CONFIG_PSA_WANT_KEY_TYPE_ECC_KEY_PAIR_EXPORT=y
CONFIG_PSA_WANT_KEY_TYPE_ECC_KEY_PAIR_GENERATE=y

# ECDSA (required for ECDHE-ECDSA cipher suites and verifying EC server certificates)
CONFIG_PSA_WANT_ALG_ECDSA=y
CONFIG_PSA_WANT_ALG_DETERMINISTIC_ECDSA=y
CONFIG_PSA_WANT_ALG_HMAC=y

# ECDH (required for ECDHE key exchange in all ECDHE cipher suites)
CONFIG_PSA_WANT_ALG_ECDH=y

# ECDHE key exchange (TLS ciphersuite level, still current symbols)
CONFIG_MBEDTLS_KEY_EXCHANGE_ECDHE_ECDSA_ENABLED=y
CONFIG_MBEDTLS_KEY_EXCHANGE_ECDHE_RSA_ENABLED=y

# RSA
CONFIG_PSA_WANT_KEY_TYPE_RSA_PUBLIC_KEY=y
CONFIG_PSA_WANT_KEY_TYPE_RSA_KEY_PAIR_IMPORT=y
CONFIG_PSA_WANT_KEY_TYPE_RSA_KEY_PAIR_EXPORT=y
CONFIG_PSA_WANT_ALG_RSA_PKCS1V15_SIGN=y
CONFIG_PSA_WANT_ALG_RSA_PKCS1V15_CRYPT=y
CONFIG_MBEDTLS_MPI_MAX_SIZE=512
CONFIG_PSA_WANT_RSA_KEY_SIZE_2048=y
CONFIG_PSA_WANT_RSA_KEY_SIZE_4096=y

# SHA
CONFIG_PSA_WANT_ALG_SHA_256=y
CONFIG_PSA_WANT_ALG_SHA_512=y

# PSK
CONFIG_MBEDTLS_KEY_EXCHANGE_PSK_ENABLED=y

# Disable unneeded modules
CONFIG_MBEDTLS_CTR_DRBG_C=n

# Disable SM functionality to free flash
CONFIG_SM_GNSS=n
CONFIG_SM_SMS=n
CONFIG_SM_MQTTC=n
CONFIG_NRF_CLOUD=n
CONFIG_NRF_CLOUD_COAP=n
CONFIG_NRF_CLOUD_AGNSS=n
CONFIG_MODEM_CMUX=n
```

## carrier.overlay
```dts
/*
 * Copyright (c) 2026 Nordic Semiconductor ASA
 *
 * SPDX-License-Identifier: LicenseRef-Nordic-5-Clause
 *
 * Flash partition overlay for nRF9151DK with LwM2M carrier partition.
 *
 * LwM2M carrier utilizes the memfault coredump partition as a lwM2M settings partition
 * and falls back to a RAM-backed coredump.
 */

/ {
	chosen {
		nordic,lwm2m-carrier-partition = &lwm2m_carrier_partition;
		zephyr,settings_partition = &settings_storage_partition;
		/delete-property/ nordic,memfault-coredump-partition;
	};
};

/delete-node/ &memfault_coredump_partition;

&storage_partition {
	compatible = "zephyr,mapped-partition";
	label = "storage";
	reg = <0x000fb000 0x5000>;
	ranges = <0x0 0x000fb000 0x5000>;
	#address-cells = <1>;
	#size-cells = <1>;

	lwm2m_carrier_partition: partition@0 {
		compatible = "zephyr,mapped-partition";
		label = "lwm2m-carrier";
		reg = <0x00000000 0x3000>;
	};

	settings_storage_partition: partition@3000 {
		compatible = "zephyr,mapped-partition";
		label = "settings-storage";
		reg = <0x00003000 0x2000>;
	};
};
```

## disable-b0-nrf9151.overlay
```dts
/*
 * Copyright (c) 2026 Nordic Semiconductor ASA
 *
 * SPDX-License-Identifier: LicenseRef-Nordic-5-Clause
 *
 * Flash partition layout for nRF9151 DK with MCUBoot.
 *
 * 0x0000_0000  s0 (MCUBoot image, slot 0)   ( 64 kB)
 * 0x0001_0000  slot0 (primary app)          (472 kB)
 *   0x0001_0000  TF-M secure                ( 32 kB)
 *   0x0001_8000  Application (non-secure)   (440 kB - (MCUBoot swap sector + MCUboot trailer))
 * 0x0008_6000  slot1 (secondary app)        (472 kB)
 * 0x000f_c000  Non-secure storage           ( 16 kB)
 */

/ {
	chosen {
		zephyr,settings_partition = &storage_partition;
		/delete-property/ nordic,memfault-coredump-partition;
	};
};

/delete-node/ &b0_partition;
/delete-node/ &s0_partition;
/delete-node/ &s1_partition;
/delete-node/ &slot0_partition;
/delete-node/ &slot1_partition;
/delete-node/ &storage_partition;

&flash0 {
	partitions {
		s0_partition: boot_partition: partition@0 {
			compatible = "zephyr,mapped-partition";
			label = "mcuboot-0";
			reg = <0x0 0x10000>;
		};

		slot0_partition: partition@10000 {
			compatible = "zephyr,mapped-partition";
			label = "image-0";
			reg = <0x10000 0x76000>;
			ranges = <0x0 0x10000 0x76000>;
			#address-cells = <1>;
			#size-cells = <1>;

			slot0_s_partition: partition@0 {
				compatible = "zephyr,mapped-partition";
				label = "image-0-secure";
				reg = <0x0 0x8000>;
			};

			slot0_ns_partition: partition@8000 {
				compatible = "zephyr,mapped-partition";
				label = "image-0-nonsecure";
				reg = <0x8000 0x6e000>;
			};
		};

		slot1_partition: partition@86000 {
			compatible = "zephyr,mapped-partition";
			label = "image-1";
			reg = <0x86000 0x76000>;
			ranges = <0x0 0x86000 0x76000>;
			#address-cells = <1>;
			#size-cells = <1>;

			slot1_s_partition: partition@0 {
				compatible = "zephyr,mapped-partition";
				label = "image-1-secure";
				reg = <0x0 0x8000>;
			};

			slot1_ns_partition: partition@8000 {
				compatible = "zephyr,mapped-partition";
				label = "image-1-nonsecure";
				reg = <0x8000 0x6e000>;
			};
		};

		storage_partition: partition@fc000 {
			compatible = "zephyr,mapped-partition";
			label = "nonsecure-storage";
			reg = <0xfc000 0x4000>;
		};
	};
};
```

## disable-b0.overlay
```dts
/*
 * Copyright (c) 2026 Nordic Semiconductor ASA
 *
 * SPDX-License-Identifier: LicenseRef-Nordic-5-Clause
 *
 * Flash partition layout for nRF9151 DK with MCUBoot.
 *
 * 0x0000_0000  s0 (MCUBoot image, slot 0)   ( 64 kB)
 * 0x0001_0000  slot0 (primary app)          (472 kB)
 *   0x0001_0000  TF-M secure                ( 32 kB)
 *   0x0001_8000  Application (non-secure)   (440 kB - (MCUBoot swap sector + MCUboot trailer))
 * 0x0008_6000  slot1 (secondary app)        (472 kB)
 * 0x000f_c000  Non-secure storage           ( 16 kB)
 */

/delete-node/ &b0_partition;
/delete-node/ &s0_partition;
/delete-node/ &s1_partition;
/delete-node/ &slot0_partition;
/delete-node/ &slot1_partition;
/delete-node/ &nonsecure_storage;

&flash0 {
	partitions {
		s0_partition: boot_partition: partition@0 {
			compatible = "zephyr,mapped-partition";
			label = "mcuboot-0";
			reg = <0x0 0x10000>;
		};

		slot0_partition: partition@10000 {
			compatible = "zephyr,mapped-partition";
			label = "image-0";
			reg = <0x10000 0x76000>;
			ranges = <0x0 0x10000 0x76000>;
			#address-cells = <1>;
			#size-cells = <1>;

			slot0_s_partition: partition@0 {
				compatible = "zephyr,mapped-partition";
				label = "image-0-secure";
				reg = <0x0 0x8000>;
			};

			slot0_ns_partition: partition@8000 {
				compatible = "zephyr,mapped-partition";
				label = "image-0-nonsecure";
				reg = <0x8000 0x6e000>;
			};
		};

		slot1_partition: partition@86000 {
			compatible = "zephyr,mapped-partition";
			label = "image-1";
			reg = <0x86000 0x76000>;
			ranges = <0x0 0x86000 0x76000>;
			#address-cells = <1>;
			#size-cells = <1>;

			slot1_s_partition: partition@0 {
				compatible = "zephyr,mapped-partition";
				label = "image-1-secure";
				reg = <0x0 0x8000>;
			};

			slot1_ns_partition: partition@8000 {
				compatible = "zephyr,mapped-partition";
				label = "image-1-nonsecure";
				reg = <0x8000 0x6e000>;
			};
		};

		nonsecure_storage: storage_partition: partition@fc000 {
			compatible = "zephyr,mapped-partition";
			label = "nonsecure-storage";
			reg = <0xfc000 0x4000>;
		};
	};
};

/ {
	/delete-node/ nordic-tz-secure;
	/delete-node/ nordic-tz-nonsecure;

	nordic-tz-secure {
		compatible = "nordic,tz-secure";
		code-partitions = <&s0_partition>,
				  <&slot0_s_partition>,
				  <&slot1_s_partition>;
	};

	nordic-tz-nonsecure {
		compatible = "nordic,tz-nonsecure";
		code-partitions = <&slot0_ns_partition>,
				  <&slot1_ns_partition>;
		data-partitions = <&storage_partition>;
	};
};
```

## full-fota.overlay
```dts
/*
 * Copyright (c) 2026 Nordic Semiconductor ASA
 *
 * SPDX-License-Identifier: LicenseRef-Nordic-5-Clause
 *
 */

/ {
	chosen {
		nordic,fmfu_storage_partition = &fmfu_storage_partition;
	};
};

/*
 * External flash layout for nRF9151 DK with full modem FOTA:
 *
 * 0x0000_0000  fmfu_storage_partition   (4 MB)
 */

&gd25wb256 {
	status = "okay";

	partitions {
		compatible = "fixed-partitions";
		#address-cells = <1>;
		#size-cells = <1>;

		fmfu_storage_partition: partition@0 {
			label = "fmfu-storage";
			reg = <0x0 0x400000>;
		};
	};
};
```

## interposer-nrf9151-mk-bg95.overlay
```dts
/*
 * Copyright (c) 2026 Nordic Semiconductor ASA
 *
 * SPDX-License-Identifier: LicenseRef-Nordic-5-Clause
 */

&pinctrl {
	uart0_default_nrf9151_mk_bg95: uart0_default_nrf9151_mk_bg95 {
		group1 {
			psels = <NRF_PSEL(UART_TX, 0, 15)>,
				<NRF_PSEL(UART_RTS, 0, 18)>;
		};
		group2 {
			psels = <NRF_PSEL(UART_RX, 0, 14)>,
				<NRF_PSEL(UART_CTS, 0, 19)>;
			bias-pull-up;
		};
	};

	uart0_sleep_nrf9151_mk_bg95: uart0_sleep_nrf9151_mk_bg95 {
		group1 {
			psels = <NRF_PSEL(UART_TX, 0, 15)>,
				<NRF_PSEL(UART_RX, 0, 14)>,
				<NRF_PSEL(UART_RTS, 0, 18)>,
				<NRF_PSEL(UART_CTS, 0, 19)>;
			low-power-enable;
		};
	};
};

&uart0 {
	status = "okay";
	/delete-property/ hw-flow-control;
	pinctrl-0 = <&uart0_default_nrf9151_mk_bg95>;
	pinctrl-1 = <&uart0_sleep_nrf9151_mk_bg95>;
	pinctrl-names = "default", "sleep";
};

/* Disable external flash */
&gd25wb256 {
	status = "disabled";
};
```

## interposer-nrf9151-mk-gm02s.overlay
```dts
/*
 * Copyright (c) 2026 Nordic Semiconductor ASA
 *
 * SPDX-License-Identifier: LicenseRef-Nordic-5-Clause
 */

&pinctrl {
	uart0_default_nrf9151_mk_gm02s: uart0_default_nrf9151_mk_gm02s {
		group1 {
			psels = <NRF_PSEL(UART_TX, 0, 8)>,
				<NRF_PSEL(UART_RTS, 0, 5)>;
		};
		group2 {
			psels = <NRF_PSEL(UART_RX, 0, 7)>,
				<NRF_PSEL(UART_CTS, 0, 4)>;
			bias-pull-up;
		};
	};

	uart0_sleep_nrf9151_mk_gm02s: uart0_sleep_nrf9151_mk_gm02s {
		group1 {
			psels = <NRF_PSEL(UART_TX, 0, 8)>,
				<NRF_PSEL(UART_RTS, 0, 5)>,
				<NRF_PSEL(UART_RX, 0, 7)>,
				<NRF_PSEL(UART_CTS, 0, 4)>;
			low-power-enable;
		};
	};
};

&uart0 {
	status = "okay";
	current-speed = <115200>;
	pinctrl-0 = <&uart0_default_nrf9151_mk_gm02s>;
	pinctrl-1 = <&uart0_sleep_nrf9151_mk_gm02s>;
	pinctrl-names = "default", "sleep";
};

/* Disable external flash */
&gd25wb256 {
	status = "disabled";
};

/* RI, CTS and RTS pins are used as LED pins in nRF9151 DK default. */
&led0 { status = "disabled"; };
&led1 { status = "disabled"; };
&led2 { status = "disabled"; };
&led3 { status = "disabled"; };
&pwm_led0 { status = "disabled"; };

/* TX pin is used as a button pin in nRF9151 DK default. */
&button0 { status = "disabled"; };
&button1 { status = "disabled"; };
&button2 { status = "disabled"; };
&button3 { status = "disabled"; };

&dtr_uart0 {
	dtr-gpios = <&gpio0 15 (GPIO_PULL_UP | GPIO_ACTIVE_HIGH)>;
};

&gpio0 {
	sense-edge-mask = <BIT(15)>;
};
```

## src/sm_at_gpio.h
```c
/*
 * Copyright (c) 2021 Nordic Semiconductor ASA
 *
 * SPDX-License-Identifier: LicenseRef-Nordic-5-Clause
 */

#ifndef SM_AT_GPIO_
#define SM_AT_GPIO_

/**@file sm_at_gpio.h
 *
 * @brief Vendor-specific AT command for GPIO service.
 * @{
 */

/**
 * @brief Initialize GPIO AT command parser.
 *
 * @retval 0 If the operation was successful.
 *           Otherwise, a (negative) error code is returned.
 */
int sm_at_gpio_init(void);

/**
 * @brief Uninitialize GPIO AT command parser.
 *
 * @retval 0 If the operation was successful.
 *           Otherwise, a (negative) error code is returned.
 */
int sm_at_gpio_uninit(void);

/** @} */

#endif /* SM_AT_GPIO_ */
```
